# D1H register map
Vendor: Allwinner; File version: 1.0
Registers are 32-bit, read-write, reset 0x0 unless marked. A register's access mark holds for its fields unless they carry their own. Offsets are from the block's base; [hi:lo] are bit positions; {n}, {i} and the like mark numbered series; 'fields as' and 'values as' point back to an identical list.

## CCU — Clock Controller Unit
Base 0x02001000
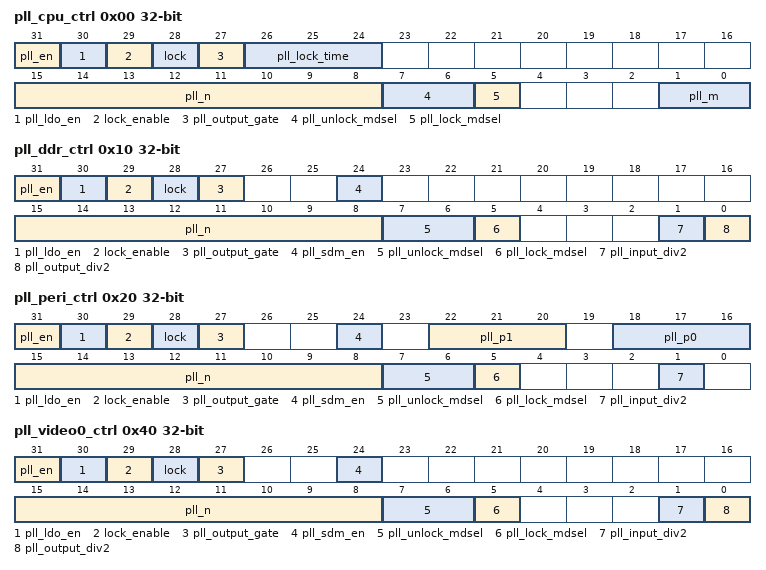
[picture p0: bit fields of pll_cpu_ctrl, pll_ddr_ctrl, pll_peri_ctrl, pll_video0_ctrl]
0x00 pll_cpu_ctrl — PLL_CPU Control Register
  [31] pll_en — PLL Enable
    0=DISABLE; 1=ENABLE
  [30] pll_ldo_en — LDO Enable
    0=DISABLE; 1=ENABLE
  [29] lock_enable
    0=DISABLE; 1=ENABLE
  [28] lock ro — PLL Lock Status
    0=UNLOCKED; 1=LOCKED
  [27] pll_output_gate — PLL Output Gating Enable
    0=DISABLE; 1=ENABLE
  [26:24] pll_lock_time
  [15:8] pll_n
  [7:6] pll_unlock_mdsel — PLL Unlock Level
    0=CC_21_29; 1=CC_22_28; 2=CC_20_30
  [5] pll_lock_mdsel — PLL Lock Level
    0=CC_24_26; 1=CC_23_27
  [1:0] pll_m
0x10 pll_ddr_ctrl — PLL_DDR Control Register
  [31] pll_en — PLL Enable
    0=DISABLE; 1=ENABLE
  [30] pll_ldo_en — LDO Enable
    0=DISABLE; 1=ENABLE
  [29] lock_enable
    0=DISABLE; 1=ENABLE
  [28] lock ro — PLL Lock Status
    0=UNLOCKED; 1=LOCKED
  [27] pll_output_gate — PLL Output Gating Enable
    0=DISABLE; 1=ENABLE
  [24] pll_sdm_en — PLL SDM Enable
    0=DISABLE; 1=ENABLE
  [15:8] pll_n
  [7:6] pll_unlock_mdsel — PLL Unlock Level
    0=CC_21_29; 1=CC_22_28; 2=CC_20_30
  [5] pll_lock_mdsel — PLL Lock Level
    0=CC_24_26; 1=CC_23_27
  [1] pll_input_div2 — PLL Input Div M1
  [0] pll_output_div2 — PLL Output Div M0
0x20 pll_peri_ctrl — PLL_PERI Control Register
  [31] pll_en — PLL Enable
    0=DISABLE; 1=ENABLE
  [30] pll_ldo_en — LDO Enable
    0=DISABLE; 1=ENABLE
  [29] lock_enable
    0=DISABLE; 1=ENABLE
  [28] lock ro — PLL Lock Status
    0=UNLOCKED; 1=LOCKED
  [27] pll_output_gate — PLL Output Gating Enable
    0=DISABLE; 1=ENABLE
  [24] pll_sdm_en — PLL SDM Enable
    0=DISABLE; 1=ENABLE
  [22:20] pll_p1 — PLL Output Div P1
  [18:16] pll_p0 — PLL Output Div P0
  [15:8] pll_n
  [7:6] pll_unlock_mdsel — PLL Unlock Level
    0=CC_21_29; 1=CC_22_28; 2=CC_20_30
  [5] pll_lock_mdsel — PLL Lock Level
    0=CC_24_26; 1=CC_23_27
  [1] pll_input_div2 — PLL Input Div M
0x40 pll_video0_ctrl — PLL_VIDEO0 Control Register
  [31] pll_en — PLL Enable
    0=DISABLE; 1=ENABLE
  [30] pll_ldo_en — LDO Enable
    0=DISABLE; 1=ENABLE
  [29] lock_enable
    0=DISABLE; 1=ENABLE
  [28] lock ro — PLL Lock Status
    0=UNLOCKED; 1=LOCKED
  [27] pll_output_gate — PLL Output Gating Enable
    0=DISABLE; 1=ENABLE
  [24] pll_sdm_en — PLL SDM Enable
    0=DISABLE; 1=ENABLE
  [15:8] pll_n
  [7:6] pll_unlock_mdsel — PLL Unlock Level
    0=CC_21_29; 1=CC_22_28; 2=CC_20_30
  [5] pll_lock_mdsel — PLL Lock Level
    0=CC_24_26; 1=CC_23_27
  [1] pll_input_div2 — PLL Input Div M
  [0] pll_output_div2 — PLL Output Div D
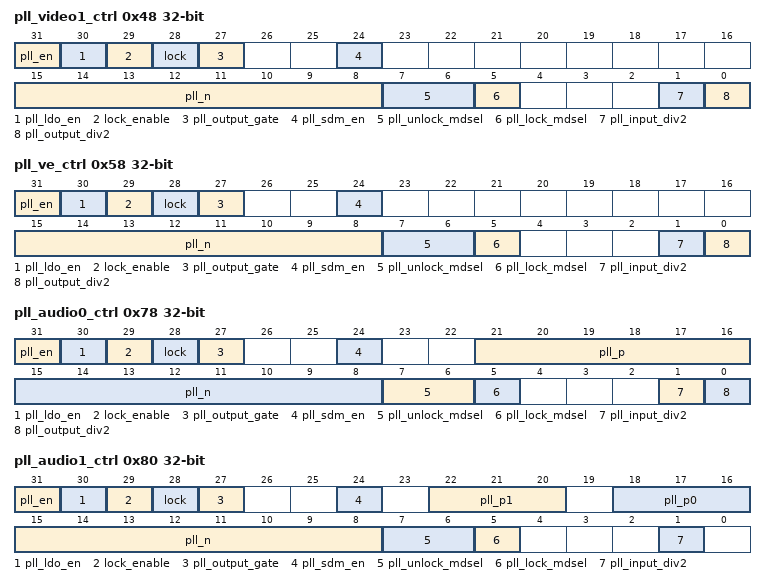
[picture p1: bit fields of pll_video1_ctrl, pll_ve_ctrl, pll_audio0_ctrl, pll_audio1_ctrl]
0x48 pll_video1_ctrl — PLL_VIDEO1 Control Register
  fields as pll_video0_ctrl
0x58 pll_ve_ctrl — PLL_VE Control Register
  fields as pll_ddr_ctrl
0x78 pll_audio0_ctrl — PLL_AUDIO0 Control Register
  [31] pll_en — PLL Enable
    0=DISABLE; 1=ENABLE
  [30] pll_ldo_en — LDO Enable
    0=DISABLE; 1=ENABLE
  [29] lock_enable
    0=DISABLE; 1=ENABLE
  [28] lock ro — PLL Lock Status
    0=UNLOCKED; 1=LOCKED
  [27] pll_output_gate — PLL Output Gating Enable
    0=DISABLE; 1=ENABLE
  [24] pll_sdm_en — PLL SDM Enable
    0=DISABLE; 1=ENABLE
  [21:16] pll_p — PLL Post-div P
  [15:8] pll_n
  [7:6] pll_unlock_mdsel — PLL Unlock Level
    0=CC_21_29; 1=CC_22_28; 2=CC_20_30
  [5] pll_lock_mdsel — PLL Lock Level
    0=CC_24_26; 1=CC_23_27
  [1] pll_input_div2 — PLL Input Div M1
  [0] pll_output_div2 — PLL Output Div M0
0x80 pll_audio1_ctrl — PLL_AUDIO1 Control Register
  fields as pll_peri_ctrl
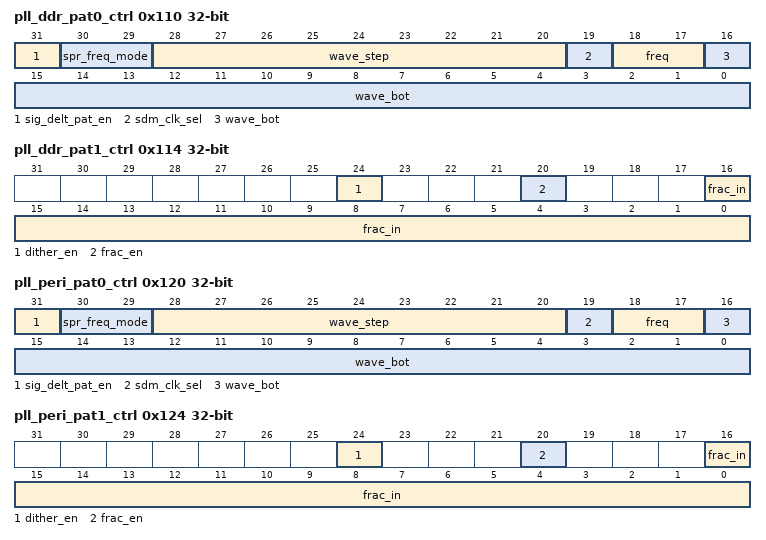
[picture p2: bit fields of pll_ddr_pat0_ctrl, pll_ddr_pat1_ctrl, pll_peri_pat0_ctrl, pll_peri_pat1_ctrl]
0x110 pll_ddr_pat0_ctrl — PLL_DDR Pattern0 Control Register
  [31] sig_delt_pat_en — Sigma-Delta Pattern Enable
  [30:29] spr_freq_mode — Spread Frequency Mode
    0=DC0; 1=DC1; 2=TRIANGULAR_1; 3=TRIANGULAR_N
  [28:20] wave_step
  [19] sdm_clk_sel — SDM Clock Select
    0=F_24_M; 1=F_12_M
  [18:17] freq — Frequency
    0=F_31_5_K; 1=F_32_K; 2=F_32_5_K; 3=F_33_K
  [16:0] wave_bot — Wave Bottom
0x114 pll_ddr_pat1_ctrl — PLL_DDR Pattern1 Control Register
  [24] dither_en — Dither Enable
  [20] frac_en — Fraction Enable
  [16:0] frac_in — Fraction In
0x120 pll_peri_pat0_ctrl — PLL_PERI Pattern0 Control Register
  fields as pll_ddr_pat0_ctrl
0x124 pll_peri_pat1_ctrl — PLL_PERI Pattern1 Control Register
  fields as pll_ddr_pat1_ctrl
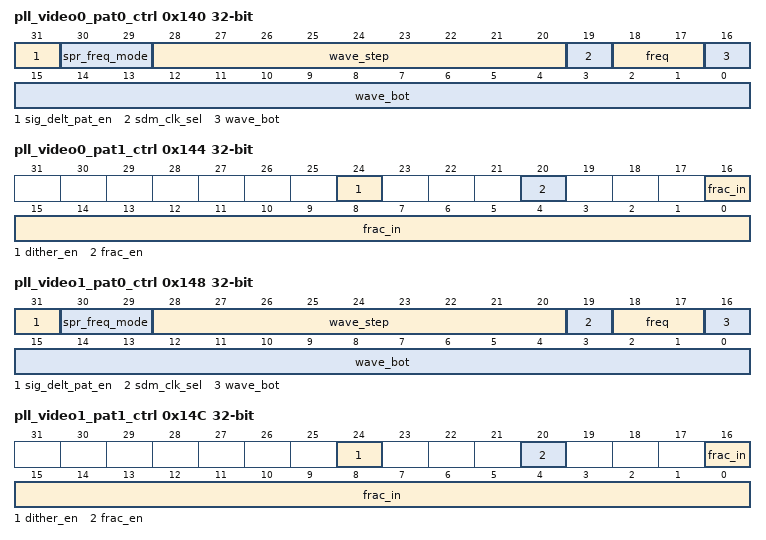
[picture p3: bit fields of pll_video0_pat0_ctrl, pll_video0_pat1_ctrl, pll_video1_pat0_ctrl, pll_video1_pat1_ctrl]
0x140 pll_video0_pat0_ctrl — PLL_VIDEO0 Pattern0 Control Register
  fields as pll_ddr_pat0_ctrl
0x144 pll_video0_pat1_ctrl — PLL_VIDEO0 Pattern1 Control Register
  fields as pll_ddr_pat1_ctrl
0x148 pll_video1_pat0_ctrl — PLL_VIDEO1 Pattern0 Control Register
  fields as pll_ddr_pat0_ctrl
0x14C pll_video1_pat1_ctrl — PLL_VIDEO1 Pattern1 Control Register
  fields as pll_ddr_pat1_ctrl
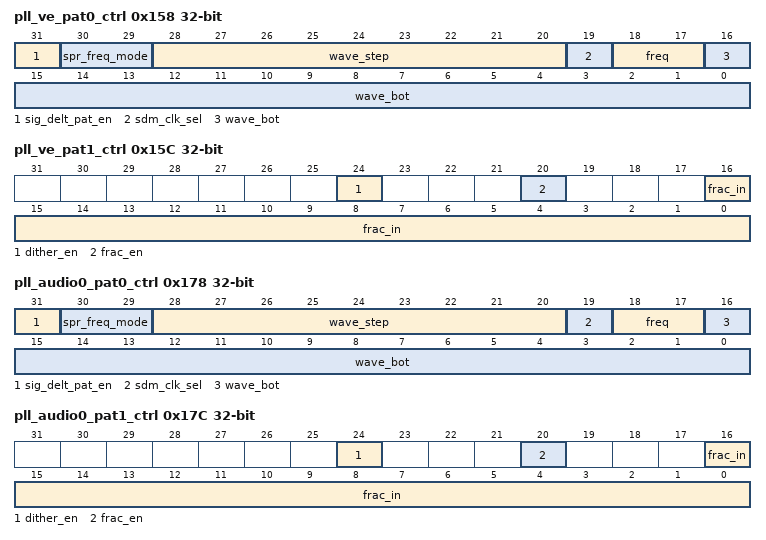
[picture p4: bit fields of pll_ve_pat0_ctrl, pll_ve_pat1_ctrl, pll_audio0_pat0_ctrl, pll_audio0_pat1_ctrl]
0x158 pll_ve_pat0_ctrl — PLL_VE Pattern0 Control Register
  fields as pll_ddr_pat0_ctrl
0x15C pll_ve_pat1_ctrl — PLL_VE Pattern1 Control Register
  fields as pll_ddr_pat1_ctrl
0x178 pll_audio0_pat0_ctrl — PLL_AUDIO0 Pattern0 Control Register
  fields as pll_ddr_pat0_ctrl
0x17C pll_audio0_pat1_ctrl — PLL_AUDIO0 Pattern1 Control Register
  fields as pll_ddr_pat1_ctrl
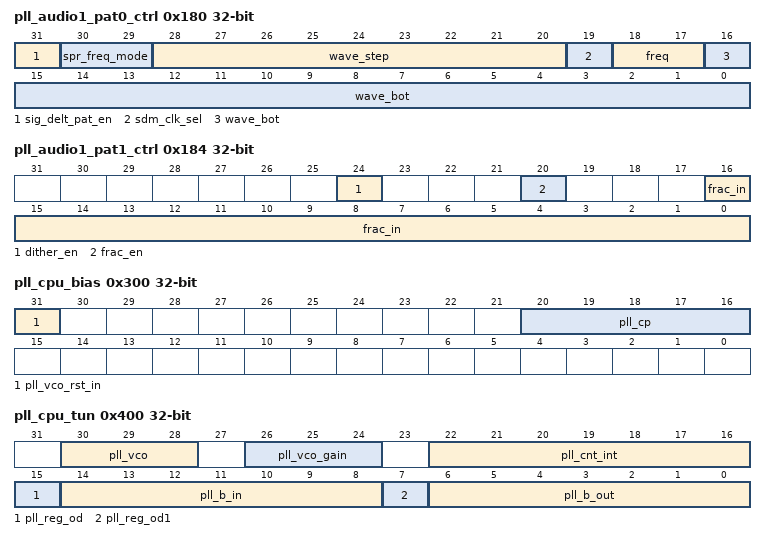
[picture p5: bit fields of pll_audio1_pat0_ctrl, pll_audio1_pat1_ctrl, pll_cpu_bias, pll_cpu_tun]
0x180 pll_audio1_pat0_ctrl — PLL_AUDIO1 Pattern0 Control Register
  fields as pll_ddr_pat0_ctrl
0x184 pll_audio1_pat1_ctrl — PLL_AUDIO1 Pattern1 Control Register
  fields as pll_ddr_pat1_ctrl
0x300 pll_cpu_bias
  [31] pll_vco_rst_in — VCO reset in
  [20:16] pll_cp — PLL current bias control
0x310 pll_ddr_bias
  [20:16] pll_cp — PLL current bias control
0x320 pll_peri_bias
  [20:16] pll_cp — PLL current bias control
0x340 pll_video0_bias
  [20:16] pll_cp — PLL current bias control
0x348 pll_video1_bias
  [20:16] pll_cp — PLL current bias control
0x358 pll_ve_bias
  [20:16] pll_cp — PLL current bias control
0x378 pll_audio0_bias
  [20:16] pll_cp — PLL current bias control
0x380 pll_audio1_bias
  [20:16] pll_cp — PLL current bias control
0x400 pll_cpu_tun — PLL_CPU Tuning Register
  [30:28] pll_vco — VCO range control
  [26:24] pll_vco_gain — KVCO gain control
  [22:16] pll_cnt_int — Counter initial control
  [15] pll_reg_od — PLL-REG-OD0 for verify
  [14:8] pll_b_in — PLL-B-IN [6:0] for verify
  [7] pll_reg_od1 — PLL-REG-OD1 for verify
  [6:0] pll_b_out ro — PLL-B-OUT [6:0] for verify
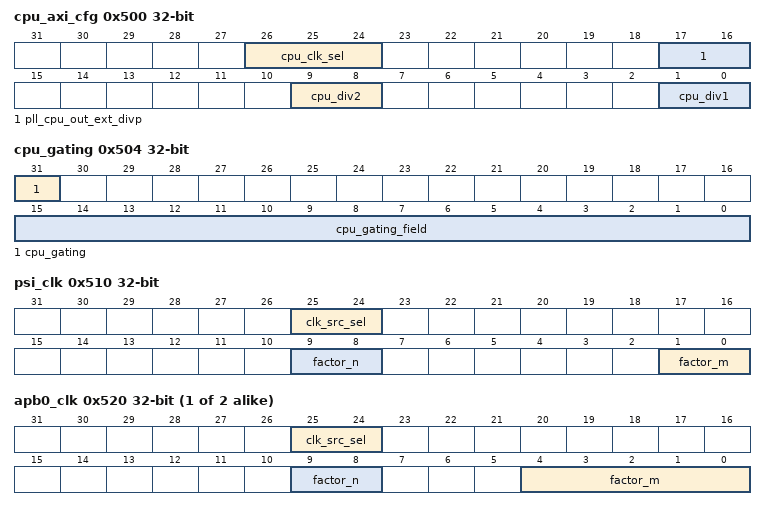
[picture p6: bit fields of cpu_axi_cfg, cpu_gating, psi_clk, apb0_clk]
0x500 cpu_axi_cfg — CPU_AXI Configuration Register
  [26:24] cpu_clk_sel — Clock Source Select
    0=HOSC; 1=CLK32K; 2=CLK16M_RC; 3=PLL_CPU_P; 4=PLL_PERI_1X; 5=PLL_PERI_2X; 6=PLL_PERI_800M
  [17:16] pll_cpu_out_ext_divp — PLL Output External Divider P
    0=P1; 1=P2; 2=P4
  [9:8] cpu_div2 — Factor N
  [1:0] cpu_div1 — Factor M
0x504 cpu_gating — CPU_GATING Configuration Register
  [31] cpu_gating — Gating Special Clock
    0=OFF; 1=ON
  [15:0] cpu_gating_field
0x510 psi_clk — PSI Clock Register
  [25:24] clk_src_sel — Clock Source Select
    0=HOSC; 1=CLK32K; 2=CLK16M_RC; 3=PLL_PERI_1X
  [9:8] factor_n
    0=N1; 1=N2; 2=N4; 3=N8
  [1:0] factor_m
{0x520+4i} apb{i}_clk (i=0..1) — APB Clock Register
  [25:24] clk_src_sel — Clock Source Select
    0=HOSC; 1=CLK32K; 2=PSI_CLK; 3=PLL_PERI_1X
  [9:8] factor_n
    0=N1; 1=N2; 2=N4; 3=N8
  [4:0] factor_m
0x540 mbus_clk — MBUS Clock Register
  [30] mbus_rst — MBUS Reset
    0=ASSERT; 1=DEASSERT
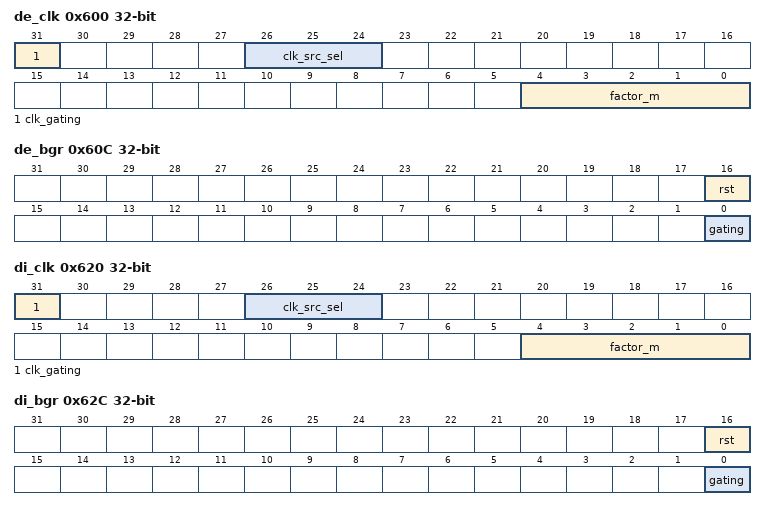
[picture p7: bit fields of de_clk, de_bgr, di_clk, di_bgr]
0x600 de_clk — DE Clock Register
  [31] clk_gating — Gating Clock
    0=OFF; 1=ON
  [26:24] clk_src_sel — Clock Source Select
    0=PLL_PERI_2X; 1=PLL_VIDEO0_4X; 2=PLL_VIDEO1_4X; 3=PLL_AUDIO1_DIV2
  [4:0] factor_m
0x60C de_bgr — DE Bus Gating Reset Register
  [16] rst — Reset
    0=ASSERT; 1=DEASSERT
  [0] gating — Gating Clock
    0=MASK; 1=PASS
0x620 di_clk — DI Clock Register
  fields as de_clk
0x62C di_bgr — DI Bus Gating Reset Register
  fields as de_bgr
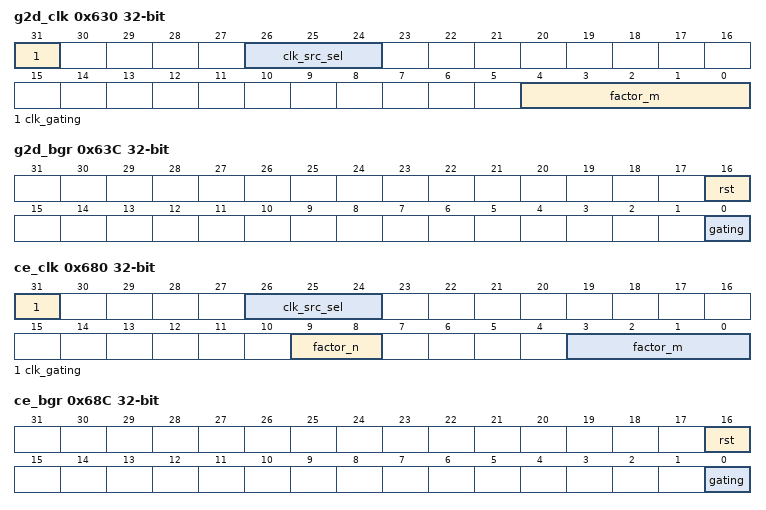
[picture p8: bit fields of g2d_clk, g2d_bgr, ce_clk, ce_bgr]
0x630 g2d_clk — G2D Clock Register
  fields as de_clk
0x63C g2d_bgr — G2D Bus Gating Reset Register
  fields as de_bgr
0x680 ce_clk — CE Clock Register
  [31] clk_gating — Gating Clock
    0=OFF; 1=ON
  [26:24] clk_src_sel — Clock Source Select
    0=HOSC; 1=PLL_PERI_2X; 2=PLL_PERI_1X
  [9:8] factor_n
    0=N1; 1=N2; 2=N4; 3=N8
  [3:0] factor_m
0x68C ce_bgr — CE Bus Gating Reset Register
  fields as de_bgr
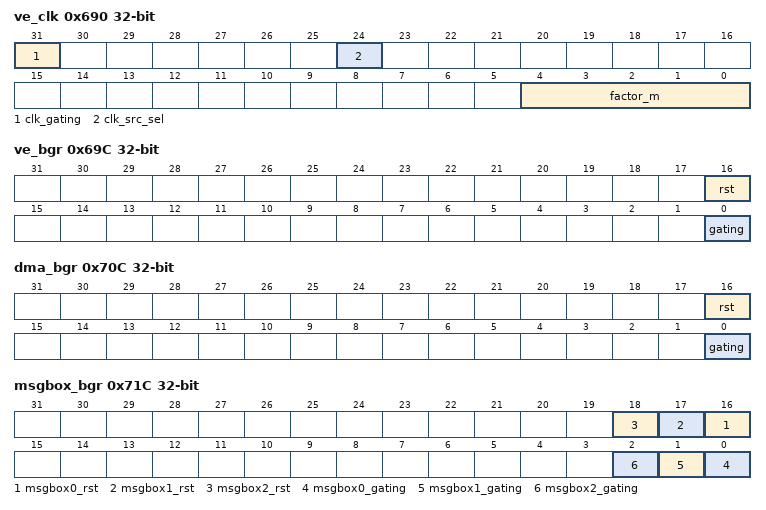
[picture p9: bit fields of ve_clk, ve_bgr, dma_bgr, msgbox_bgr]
0x690 ve_clk — VE Clock Register
  [31] clk_gating — Gating Clock
    0=OFF; 1=ON
  [24] clk_src_sel — Clock Source Select
    0=VEPLL; 1=PLL_PERI_2X
  [4:0] factor_m
0x69C ve_bgr — VE Bus Gating Reset Register
  fields as de_bgr
0x70C dma_bgr — DMA Bus Gating Reset Register
  fields as de_bgr
0x71C msgbox_bgr — MSGBOX Bus Gating Reset Register
  [n+16] msgbox{n}_rst (n=0..2) — CPU, DSP, RISC-V MSGBOX Reset
    0=ASSERT; 1=DEASSERT
  [n] msgbox{n}_gating (n=0..2) — Gating Clock for CPU, DSP, RISC-V MSGBOX
    0=MASK; 1=PASS
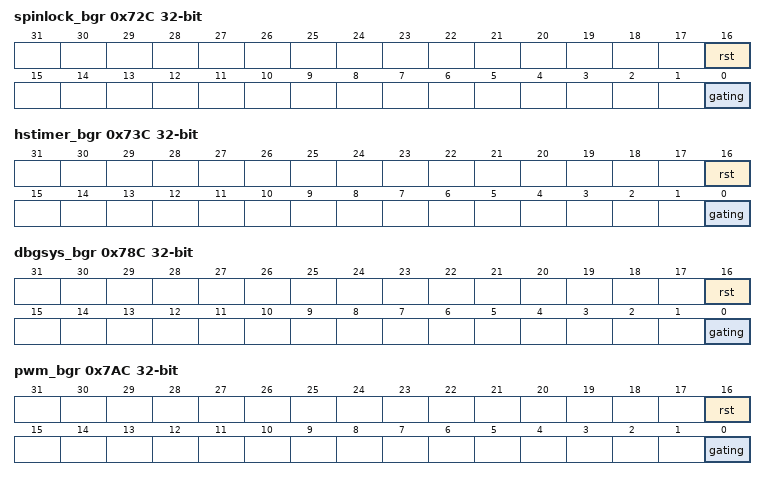
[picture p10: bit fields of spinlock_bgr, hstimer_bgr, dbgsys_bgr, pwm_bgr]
0x72C spinlock_bgr — SPINLOCK Bus Gating Reset Register
  fields as de_bgr
0x73C hstimer_bgr — HSTIMER Bus Gating Reset Register
  fields as de_bgr
0x740 avs_clk — AVS Clock Register
  [31] clk_gating — Gating Clock
    0=OFF; 1=ON
0x78C dbgsys_bgr — DBGSYS Bus Gating Reset Register
  fields as de_bgr
0x7AC pwm_bgr — PWM Bus Gating Reset Register
  fields as de_bgr
0x7BC iommu_bgr — IOMMU Bus Gating Reset Register
  [0] gating — Gating Clock
    0=MASK; 1=PASS
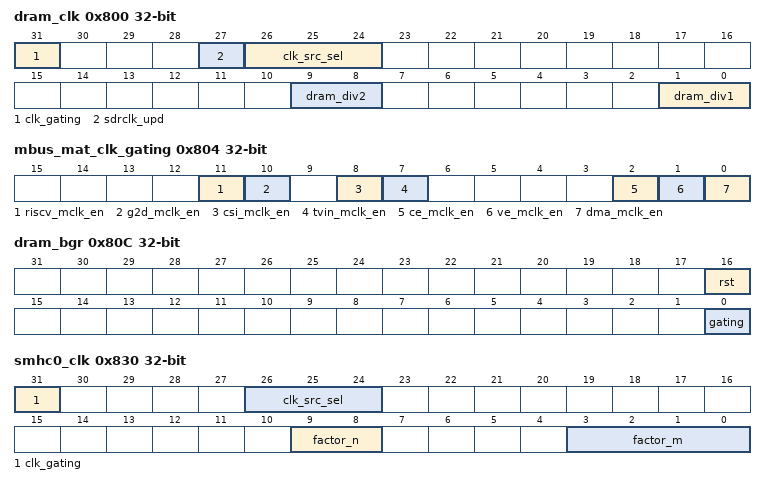
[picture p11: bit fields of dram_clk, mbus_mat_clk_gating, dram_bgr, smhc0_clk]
0x800 dram_clk — DRAM Clock Register
  [31] clk_gating — Gating Clock
    0=OFF; 1=ON
  [27] sdrclk_upd — SDRCLK Configuration 0 Update
    0=INVALID; 1=VALID
  [26:24] clk_src_sel — Clock Source Select
    0=PLL_DDR; 1=PLL_AUDIO1_DIV2; 2=PLL_PERI_2X; 3=PLL_PERI_800M
  [9:8] dram_div2 — Factor N
    0=N1; 1=N2; 2=N4; 3=N8
  [1:0] dram_div1 — Factor M
0x804 mbus_mat_clk_gating — MBUS Master Clock Gating Register
  [all] fields
    0=MASK; 1=PASS
  [11] riscv_mclk_en — Gating MBUS Clock
  [10] g2d_mclk_en — Gating MBUS Clock
  [8] csi_mclk_en — Gating MBUS Clock
  [7] tvin_mclk_en — Gating MBUS Clock
  [2] ce_mclk_en — Gating MBUS Clock
  [1] ve_mclk_en — Gating MBUS Clock
  [0] dma_mclk_en — Gating MBUS Clock
0x80C dram_bgr — DRAM Bus Gating Reset Register
  fields as de_bgr
0x830 smhc0_clk — SMHC0 Clock Register
  [31] clk_gating — Gating Clock
    0=OFF; 1=ON
  [26:24] clk_src_sel — Clock Source Select
    0=HOSC; 1=PLL_PERI_1X; 2=PLL_PERI_2X; 3=PLL_AUDIO1_DIV2
  [9:8] factor_n
    0=N1; 1=N2; 2=N4; 3=N8
  [3:0] factor_m
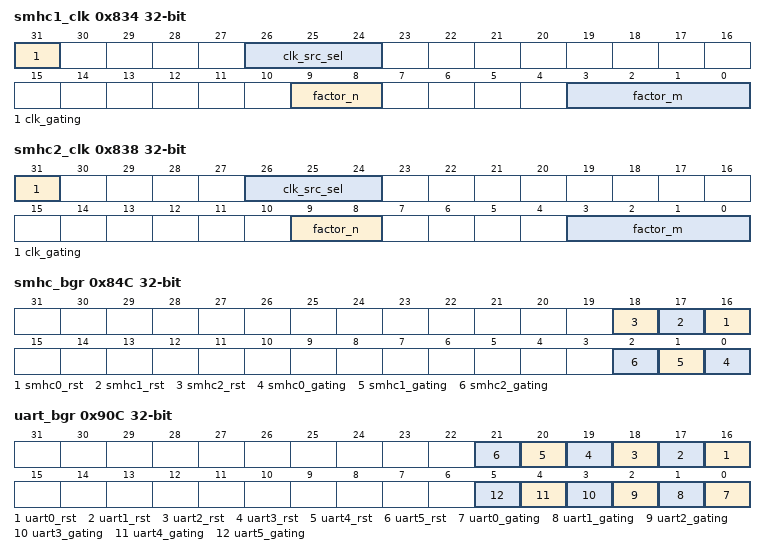
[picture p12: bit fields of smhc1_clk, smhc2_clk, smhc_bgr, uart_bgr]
0x834 smhc1_clk — SMHC1 Clock Register
  fields as smhc0_clk
0x838 smhc2_clk — SMHC2 Clock Register
  [31] clk_gating — Gating Clock
    0=OFF; 1=ON
  [26:24] clk_src_sel — Clock Source Select
    0=HOSC; 1=PLL_PERI_1X; 2=PLL_PERI_2X; 3=PLL_PERI_800M; 4=PLL_AUDIO1_DIV2
  [9:8] factor_n
    0=N1; 1=N2; 2=N4; 3=N8
  [3:0] factor_m
0x84C smhc_bgr — SMHC Bus Gating Reset Register
  [n+16] smhc{n}_rst (n=0..2) — Reset
    0=ASSERT; 1=DEASSERT
  [n] smhc{n}_gating (n=0..2) — Gating Clock
    0=MASK; 1=PASS
0x90C uart_bgr — UART Bus Gating Reset Register
  [n+16] uart{n}_rst (n=0..5) — Reset
    0=ASSERT; 1=DEASSERT
  [n] uart{n}_gating (n=0..5) — Gating Clock
    0=MASK; 1=PASS
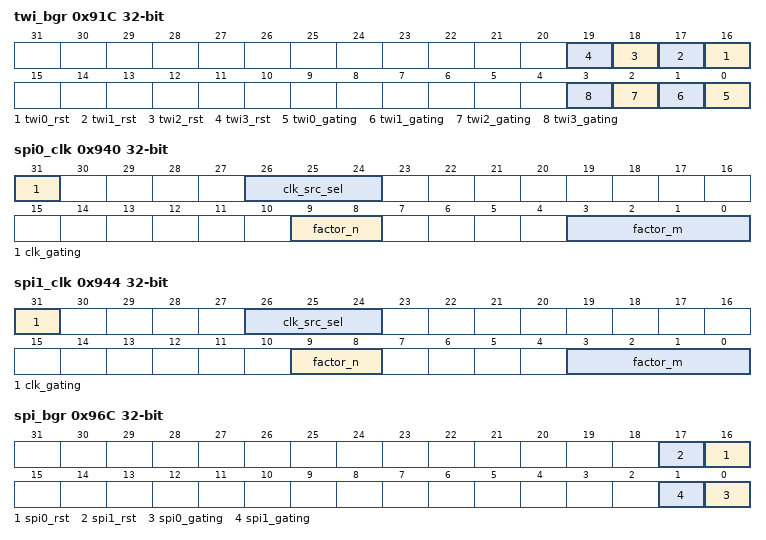
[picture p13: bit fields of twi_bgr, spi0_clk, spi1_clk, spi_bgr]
0x91C twi_bgr — TWI Bus Gating Reset Register
  [n+16] twi{n}_rst (n=0..3) — Reset
    0=ASSERT; 1=DEASSERT
  [n] twi{n}_gating (n=0..3) — Gating Clock
    0=MASK; 1=PASS
0x940 spi0_clk — SPI0 Clock Register
  [31] clk_gating — Gating Clock
    0=OFF; 1=ON
  [26:24] clk_src_sel — Clock Source Select
    0=HOSC; 1=PLL_PERI_1X; 2=PLL_PERI_2X; 3=PLL_AUDIO1_DIV2; 4=PLL_AUDIO1_DIV5
  [9:8] factor_n
    0=N1; 1=N2; 2=N4; 3=N8
  [3:0] factor_m
0x944 spi1_clk — SPI1 Clock Register
  fields as spi0_clk
0x96C spi_bgr — SPI Bus Gating Reset Register
  [n+16] spi{n}_rst (n=0..1) — Reset
    0=ASSERT; 1=DEASSERT
  [n] spi{n}_gating (n=0..1) — Gating Clock
    0=MASK; 1=PASS
0x970 emac_25m_clk — EMAC_25M Clock Register
  [31] clk_gating — Gating Special Clock
    0=OFF; 1=ON
  [31] clk_src_gating — Gating the Source Clock of Special Clock
    0=OFF; 1=ON
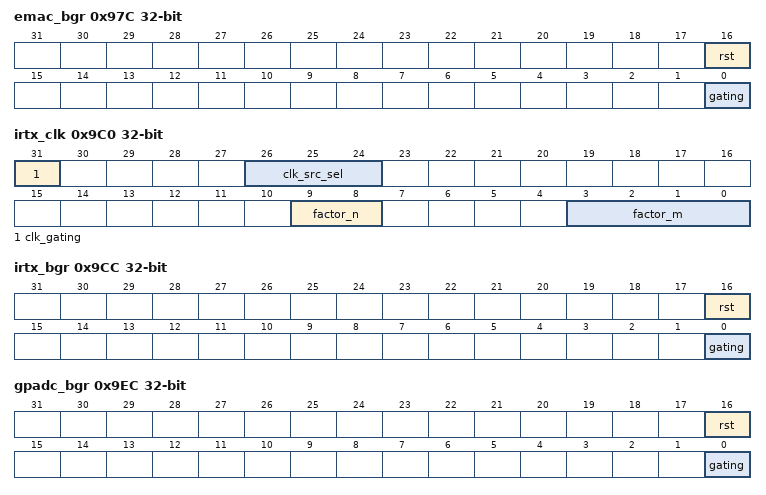
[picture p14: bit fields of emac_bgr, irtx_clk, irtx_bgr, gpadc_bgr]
0x97C emac_bgr — EMAC Bus Gating Reset Register
  fields as de_bgr
0x9C0 irtx_clk — IRTX Clock Register
  [31] clk_gating — Gating Clock
    0=OFF; 1=ON
  [26:24] clk_src_sel — Clock Source Select
    0=HOSC; 1=PLL_PERI_1X
  [9:8] factor_n
    0=N1; 1=N2; 2=N4; 3=N8
  [3:0] factor_m
0x9CC irtx_bgr — IRTX Bus Gating Reset Register
  fields as de_bgr
0x9EC gpadc_bgr — GPADC Bus Gating Reset Register
  fields as de_bgr
0x9FC ths_bgr — THS Bus Gating Reset Register
  fields as de_bgr
{0xA10+4i} i2s{i}_clk (i=0..2) — I2S Clock Register
  [31] clk_gating — Gating Clock
    0=OFF; 1=ON
  [26:24] clk_src_sel — Clock Source Select
    0=PLL_AUDIO0_1X; 1=PLL_AUDIO0_4X; 2=PLL_AUDIO1_DIV2; 3=PLL_AUDIO1_DIV5
  [9:8] factor_n
    0=N1; 1=N2; 2=N4; 3=N8
  [4:0] factor_m
0xA1C i2s2_asrc_clk — I2S2_ASRC Clock Register
  [31] clk_gating — Gating Clock
    0=OFF; 1=ON
  [26:24] clk_src_sel — Clock Source Select
    0=PLL_AUDIO0_4X; 1=PLL_PERI_1X; 2=PLL_AUDIO1_DIV2; 3=PLL_AUDIO1_DIV5
  [9:8] factor_n
    0=N1; 1=N2; 2=N4; 3=N8
  [4:0] factor_m
0xA20 i2s_bgr — I2S Bus Gating Reset Register
  [n+16] i2s{n}_rst (n=0..2) — Reset
    0=ASSERT; 1=DEASSERT
  [n] i2s{n}_gating (n=0..2) — Gating Clock
    0=MASK; 1=PASS
0xA24 owa_tx_clk — OWA_TX Clock Register
  fields as i2s0_clk
0xA28 owa_rx_clk — OWA_RX Clock Register
  [31] clk_gating — Gating Clock
    0=OFF; 1=ON
  [26:24] clk_src_sel — Clock Source Select
    0=PLL_PERI_1X; 1=PLL_AUDIO1_DIV2; 2=PLL_AUDIO1_DIV5
  [9:8] factor_n
    0=N1; 1=N2; 2=N4; 3=N8
  [4:0] factor_m
0xA2C owa_bgr — OWA Bus Gating Reset Register
  fields as de_bgr
0xA40 dmic_clk — DMIC Clock Register
  fields as owa_rx_clk
0xA4C dmic_bgr — DMIC Bus Gating Reset Register
  fields as de_bgr
0xA50 audio_codec_dac_clk — AUDIO_CODEC_DAC Clock Register
  [31] clk_gating — Gating Clock
    0=OFF; 1=ON
  [26:24] clk_src_sel — Clock Source Select
    0=PLL_AUDIO0_1X; 1=PLL_AUDIO1_DIV2; 2=PLL_AUDIO1_DIV5
  [9:8] factor_n
    0=N1; 1=N2; 2=N4; 3=N8
  [4:0] factor_m
0xA54 audio_codec_adc_clk — AUDIO_CODEC_ADC Clock Register
  fields as audio_codec_dac_clk
0xA5C audio_codec_bgr — AUDIO_CODEC Bus Gating Reset Register
  fields as de_bgr
0xA70 usb0_clk — USB0 Clock Register
  [31] clken — Gating Special Clock
    0=OFF; 1=ON
  [30] rstn — PHY Reset
    0=ASSERT; 1=DEASSERT
  [25:24] clk12m_sel — OHCI 12M Source Select
    0=DIV_48M; 1=DIV_24M; 2=RTC_32K
0xA74 usb1_clk — USB1 Clock Register
  fields as usb0_clk
0xA8C usb_bgr — USB Bus Gating Reset Register
  [24] usbotg0_rst — USBOTG0 Reset
    0=ASSERT; 1=DEASSERT
  [n+20] usbehci{n}_rst (n=0..1) — USBEHCI Reset
    0=ASSERT; 1=DEASSERT
  [n+16] usbohci{n}_rst (n=0..1) — USBOHCI Reset
    0=ASSERT; 1=DEASSERT
  [8] usbotg0_gating — USBOTG0 Gating Clock
    0=MASK; 1=PASS
  [n+4] usbehci{n}_gating (n=0..1) — USBEHCI Gating Clock
    0=MASK; 1=PASS
  [n] usbohci{n}_gating (n=0..1) — USBOHCI Gating Clock
    0=MASK; 1=PASS
0xA9C lradc_bgr — LRADC Bus Gating Reset Register
  fields as de_bgr
0xABC dpss_top_bgr — DPSS_TOP Bus Gating Reset Register
  fields as de_bgr
0xB24 dsi_clk — DSI Clock Register
  [31] clk_gating — Gating Clock
    0=OFF; 1=ON
  [26:24] clk_src_sel — Clock Source Select
    0=HOSC; 1=PLL_PERI_1X; 2=PLL_VIDEO0_2X; 3=PLL_VIDEO1_2X; 4=PLL_AUDIO1_DIV2
  [3:0] factor_m
0xB4C dsi_bgr — DSI Bus Gating Reset Register
  fields as de_bgr
0xB60 tconlcd_clk — TCONLCD Clock Register
  [31] clk_gating — Gating Clock
    0=OFF; 1=ON
  [26:24] clk_src_sel — Clock Source Select
    0=PLL_VIDEO0_1X; 1=PLL_VIDEO0_4X; 2=PLL_VIDEO1_1X; 3=PLL_VIDEO1_4X; 4=PLL_PERI_2X; 5=PLL_AUDIO1_DIV2
  [9:8] factor_n
    0=N1; 1=N2; 2=N4; 3=N8
  [3:0] factor_m
0xB7C tconlcd_bgr — TCONLCD Bus Gating Reset Register
  fields as de_bgr
0xB80 tcontv_clk — TCONTV Clock Register
  fields as tconlcd_clk
0xB9C tcontv_bgr — TCONTV Bus Gating Reset Register
  fields as de_bgr
0xBAC lvds_bgr — LVDS Bus Gating Reset Register
  [16] rst — Reset
    0=ASSERT; 1=DEASSERT
0xBB0 tve_clk — TVE Clock Register
  fields as tconlcd_clk
0xBBC tve_bgr — TVE Bus Gating Reset Register
  [17] rst — Reset
    0=ASSERT; 1=DEASSERT
  [16] top_rst — Reset
    0=ASSERT; 1=DEASSERT
  [1] gating — Gating Clock
    0=MASK; 1=PASS
  [0] top_gating — Gating Clock
    0=MASK; 1=PASS
0xBC0 tvd_clk — TVD Clock Register
  [31] clk_gating — Gating Clock
    0=OFF; 1=ON
  [26:24] clk_src_sel — Clock Source Select
    0=HOSC; 1=PLL_VIDEO0_1X; 2=PLL_VIDEO1_1X; 3=PLL_PERI_1X
  [4:0] factor_m
0xBDC tvd_bgr — TVD Bus Gating Reset Register
  fields as tve_bgr
0xBF0 ledc_clk — LEDC Clock Register
  fields as irtx_clk
0xBFC ledc_bgr — LEDC Bus Gating Reset Register
  fields as de_bgr
0xC04 csi_clk — CSI Clock Register
  [31] clk_gating — Gating Clock
    0=OFF; 1=ON
  [26:24] clk_src_sel — Clock Source Select
    0=PLL_PERI_2X; 1=PLL_VIDEO0_2X; 2=PLL_VIDEO1_2X
  [3:0] factor_m
0xC08 csi_master_clk — CSI Master Clock Register
  [31] clk_gating — Gating Clock
    0=OFF; 1=ON
  [26:24] clk_src_sel — Clock Source Select
    0=HOSC; 1=PLL_PERI_1X; 2=PLL_VIDEO0_1X; 3=PLL_VIDEO1_1X; 4=PLL_AUDIO1_DIV2; 5=PLL_AUDIO1_DIV5
  [4:0] factor_m
0xC1C csi_bgr — CSI Bus Gating Reset Register
  fields as de_bgr
0xC50 tpadc_clk — TPADC Clock Register
  [31] clk_gating — Gating Clock
    0=OFF; 1=ON
  [26:24] clk_src_sel — Clock Source Select
    0=HOSC; 1=PLL_AUDIO0_1X
0xC5C tpadc_bgr — TPADC Bus Gating Reset Register
  fields as de_bgr
0xC70 dsp_clk — DSP Clock Register
  [31] clk_gating — Gating Clock
    0=OFF; 1=ON
  [26:24] clk_src_sel — Clock Source Select
    0=HOSC; 1=CLK32K; 2=CLK16M_RC; 3=PLL_PERI_2X; 4=PLL_AUDIO1_DIV2
  [4:0] factor_m
0xC7C dsp_bgr — DSP Bus Gating Reset Register
  [18] dbg_rst — Reset
    0=ASSERT; 1=DEASSERT
  [17] cfg_rst — Reset
    0=ASSERT; 1=DEASSERT
  [16] rst — Reset
    0=ASSERT; 1=DEASSERT
  [1] cfg_gating — Gating Clock
    0=MASK; 1=PASS
0xD00 riscv_clk — RISC-V Clock Register
  [26:24] clk_src_sel — Clock Source Select
    0=HOSC; 1=CLK32K; 2=CLK16M_RC; 3=PLL_PERI_800M; 4=PLL_PERI_1X; 5=PLL_CPU; 6=PLL_AUDIO1_DIV2
  [9:8] axi_div_cfg — Factor N
  [4:0] div_cfg — Factor M
0xD04 riscv_gating — RISC-V GATING Configuration Register
  [31] gating — Gating Clock
    0=MASK; 1=PASS
  [15:0] gating_field
0xD0C riscv_cfg_bgr — RISC-V_CFG Bus Gating Reset Register
  fields as de_bgr
0xF04 pll_lock_dbg_ctrl — PLL Lock Debug Control Register
  [31] pll_lock_flag_en — Debug Enable
    0=DISABLE; 1=ENABLE
  [22:20] clk_src_sel — Clock Source Select
    0=PLL_CPUX; 1=PLL_DDR; 2=PLL_PERI_2X; 3=PLL_VIDEO0_4X; 4=PLL_VIDEO1_4X; 5=PLL_VE; 6=PLL_AUDIO0; 7=PLL_AUDIO1
0xF08 fre_det_ctrl — Frequency Detect Control Register
  [31] error_flag write-0-clears
    0=W0C; 1=ERROR
  [8:4] det_time — Detect Time
  [1] fre_det_irq_en — Frequence Detect IRQ Enable
    0=DISABLE; 1=ENABLE
  [0] fre_det_fun_en — Frequence Detect Function Enable
    0=DISABLE; 1=ENABLE
0xF0C fre_up_lim — Frequency Up Limit Register
0xF10 fre_down_lim — Frequency Down Limit Register
0xF30 ccu_fan_gate — CCU FANOUT CLOCK GATE Register
  [all] fields
    0=OFF; 1=ON
  [4] clk32k_en — Gating for CLK32K
  [3] clk25m_en — Gating for CLK25M
  [2] clk16m_en — Gating for CLK16M
  [1] clk12m_en — Gating for CLK12M
  [0] clk24m_en — Gating for CLK24M
0xF34 clk27m_fan — CLK27M FANOUT Register
  [31] gating — Gating for CLK27M
    0=OFF; 1=ON
  [25:24] clk_src_sel — Clock Source Select
    0=PLL_VIDEO0_1X; 1=PLL_VIDEO1_1X
  [9:8] div1 — Factor N
  [4:0] div0 — Factor M
0xF38 pclk_fan — PCLK FANOUT Register
  [31] gating — Gating for PCLK
    0=OFF; 1=ON
  [4:0] div — Factor M
0xF3C ccu_fan — CCU FANOUT Register
  [n+21] clk_fanout{n}_en (n=0..2) — Gating for CLK_FANOUT
    0=OFF; 1=ON
  [3n+2:3n] clk_fanout{n}_sel (n=0..2)
    0=CLK32K; 1=CLK12M; 2=CLK16M; 3=CLK24M; 4=CLK25M; 5=CLK27M; 6=PCLK
